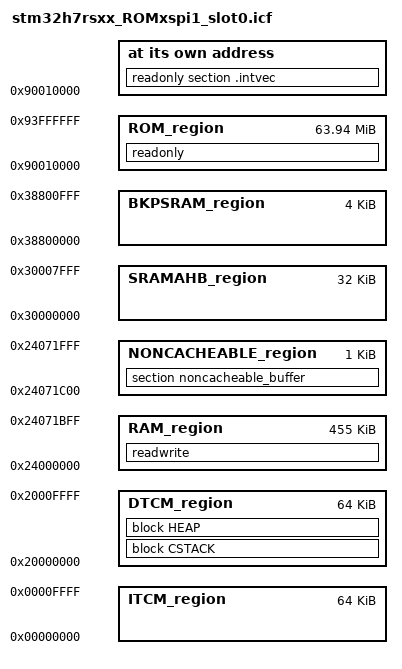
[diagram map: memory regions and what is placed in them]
/*###ICF### Section handled by ICF editor, don't touch! ****/
/*-Editor annotation file-*/
/* IcfEditorFile="$TOOLKIT_DIR$\config\ide\IcfEditor\cortex_v1_0.xml" */
/*
 * FW-Update Dual-Slot layout (Slot 0, XSPI1 NOR memory-mapped).
 *
 * External NOR Flash 128MB map:
 *   0x90000000  Slot Metadata Primary    (64KB)
 *   0x90010000  Slot 0 (Exec, XIP)       <-- this ICF places .text/.rodata here
 *   0x94000000  Slot 1 (Staging, no-XIP)
 *   0x97FF0000  Slot Metadata Backup     (64KB)
 *
 * NOTE: Appli built with this ICF must be loaded at 0x90010000 to boot.
 *       Pairs with Boot define EXTMEM_XIP_IMAGE_OFFSET=0x10000.
 *       Legacy stm32h7rsxx_ROMxspi1.icf (offset 0) kept for regression backup.
 */
/*-Specials-*/
define symbol __ICFEDIT_intvec_start__ = 0x90010000;
/*-Memory Regions-*/
define symbol __ICFEDIT_region_ROM_start__ = 0x90010000;
define symbol __ICFEDIT_region_ROM_end__   = 0x93FFFFFF;   /* Slot 0 end (just before Slot 1) */
define symbol NONCACHEABLEBUFFER_size      = 0x400;
define symbol __ICFEDIT_region_RAM_start__ = 0x24000000;
define symbol __ICFEDIT_region_RAM_end__   = 0x24071FFF - NONCACHEABLEBUFFER_size;
define symbol NONCACHEABLEBUFFER_start     = __ICFEDIT_region_RAM_end__ + 1;
define symbol NONCACHEABLEBUFFER_end       = __ICFEDIT_region_RAM_end__ + NONCACHEABLEBUFFER_size;

/*-Sizes-*/
define symbol __ICFEDIT_size_cstack__ = 0x400;
define symbol __ICFEDIT_size_heap__   = 0x200;
/**** End of ICF editor section. ###ICF###*/

define symbol __region_ITCM_start__ = 0x00000000;
define symbol __region_ITCM_end__   = 0x0000FFFF;
define symbol __region_DTCM_start__ = 0x20000000;
define symbol __region_DTCM_end__   = 0x2000FFFF;
define symbol __region_SRAMAHB_start__ = 0x30000000;
define symbol __region_SRAMAHB_end__   = 0x30007FFF;
define symbol __region_BKPSRAM_start__ = 0x38800000;
define symbol __region_BKPSRAM_end__   = 0x38800FFF;

export symbol NONCACHEABLEBUFFER_start;
export symbol NONCACHEABLEBUFFER_size;

export symbol __ICFEDIT_region_ROM_start__;
export symbol __ICFEDIT_region_ROM_end__;

define memory mem with size = 4G;
define region ROM_region      = mem:[from __ICFEDIT_region_ROM_start__ to __ICFEDIT_region_ROM_end__];
define region RAM_region      = mem:[from __ICFEDIT_region_RAM_start__ to __ICFEDIT_region_RAM_end__];
define region NONCACHEABLE_region   = mem:[from NONCACHEABLEBUFFER_start to NONCACHEABLEBUFFER_end];
define region ITCM_region     = mem:[from __region_ITCM_start__ to __region_ITCM_end__];
define region DTCM_region     = mem:[from __region_DTCM_start__ to __region_DTCM_end__];
define region SRAMAHB_region  = mem:[from __region_SRAMAHB_start__ to __region_SRAMAHB_end__];
define region BKPSRAM_region  = mem:[from __region_BKPSRAM_start__ to __region_BKPSRAM_end__];

define block CSTACK    with alignment = 8, size = __ICFEDIT_size_cstack__   { };
define block HEAP      with alignment = 8, size = __ICFEDIT_size_heap__     { };

initialize by copy { readwrite };
do not initialize  { section .noinit };

place at address mem:__ICFEDIT_intvec_start__ { readonly section .intvec };

place in ROM_region   { readonly };
place in RAM_region   { readwrite };
place in NONCACHEABLE_region { section noncacheable_buffer };
place in DTCM_region  { block CSTACK, block HEAP };
